# RTI0_CFG register map
Vendor: Texas Instruments
Peripheral module from a debugger description file (folder J7VCL).
Registers are 32-bit, read-write, reset 0x0 unless marked. A register's access mark holds for its fields unless they carry their own. Offsets are as the file gives them; lines under a group give offsets from that group; [hi:lo] are bit positions; {n}, {i} and the like mark numbered series; 'fields as' and 'values as' point back to an identical list; <NAME> marks a mode.

## RTI0_CFG
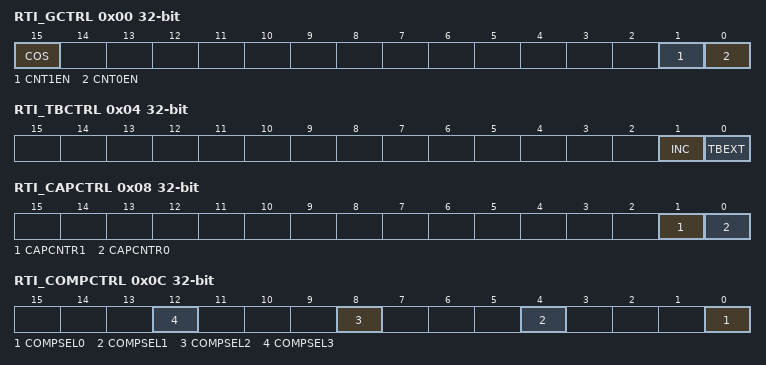
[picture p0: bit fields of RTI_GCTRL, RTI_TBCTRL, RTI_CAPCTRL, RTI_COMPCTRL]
0x00 RTI_GCTRL access per field
  [15] COS rw — Continue On Suspend. This bit determines if both counters are stopped when the device goes into debug mode or if they continue counting.
  [1] CNT1EN rw — Counter 1 Enable.
  [0] CNT0EN rw — Counter 0 Enable. The CNT0EN bit starts and stops the operation of counter block0 (UC0 and FRC0).
0x04 RTI_TBCTRL access per field
  [1] INC rw — This bit determines whether the Free Running Counter 0 is automatically incremented if a failing clock on the NTUx signal is detected.
  [0] TBEXT rw — The Timebase External bit selects whether the Free Running Counter 0 is clocked by the internal Up Counter 0 or from the external signal NTUx. Since setting the TBEXT bit to 1 resets Up Counter 0, Free Running Counter 0 will not be incremented in this occurence. The only source which is able to increment Free Running Counter 0 is NTUx. When the Timebase Supervisor circuit detects a missing clockedge, then the TBEXT bit is reset. The selection if the external signal should be used, can only be done by software.
0x08 RTI_CAPCTRL access per field
  [1] CAPCNTR1 rw — Capture Counter 1.
  [0] CAPCNTR0 rw — Capture Counter 0. This bit determines, which external interrupt source triggers a capture event of both UC0 and FRC0.
0x0C RTI_COMPCTRL access per field
  [4n] COMPSEL{n} rw (n=0..3) — Compare Select {n}. This bit determines the counter with which the compare value hold in compare register {n} is compared.
0x10 RTI_FRC0 — This registers holds the current value of the Free Running Counter 0 and will be updated continuously.
  [31:0] FRC0 — Free Running Counter 0. This registers holds the current value of the Free Running Counter 0 and will be updated continuously.
0x14 RTI_UC0
  [31:0] UC0 — Up Counter 0. This registers holds the current value of the Up Counter 0 and prescales the RTI clock. It will be only updated by a previous read of Free Running Counter 0. This gives effectively a 64 bit read of both counters, without having the problem of a counter being updated between two consecutive reads on Up Counter 0 and Free Running Counter 0.
0x18 RTI_CPUC0
  [31:0] CPUC0 — Compare Up Counter 0. This registers holds the compare value, which is compared with the Up Counter 0. When the compare matches, Free Running counter 0 is incremented. The Up Counter is set to zero when the counter value matches the CPUC0 value. The value set in this prescales the RTI.
0x20 RTI_CAFRC0 ro
  [31:0] CAFRC0 — Capture Free Running Counter 0. This registers captures the current value of the Free Running Counter 0 when an event occurs, controlled by the external capture control block.
0x24 RTI_CAUC0 ro
  [31:0] CAUC0 — Capture Up Counter 0. This registers captures the current value of the Up Counter 0 when an event occurs, controlled by the external capture control block. The read sequence has to be the same as with Up Counter 0 and Free Running Counter 0. So the
0x30 RTI_FRC1
  [31:0] FRC1 — Free Running Counter 1. This registers holds the current value of the Free Running Counter 1 and will be updated continuously.
0x34 RTI_UC1
  [31:0] UC1 — Up Counter 1. This registers holds the current value of the Up Counter 1 and prescales the RTI clock. It will be only updated by a previous read of Free Running Counter 1. This gives effectively a 64 bit read of both counters, without having the problem of a counter being updated between two consecutive reads on Up Counter 1 and Free Running Counter 1.
0x38 RTI_CPUC1
  [31:0] CPUC1 — Compare Up Counter 1. This registers holds the compare value, which is compared with the Up Counter 1. When the compare matches, Free Running counter 1 is incremented. The Up Counter is set to zero when the counter value matches the CPUC1 value. The value set in this prescales the RTI.
0x40 RTI_CAFRC1 ro
  [31:0] CAFRC1 — Capture Free Running Counter 1. This registers captures the current value of the Free Running Counter 1 when an event occurs, controlled by the external capture control block.
0x44 RTI_CAUC1 ro
  [31:0] CAUC1 — Capture Up Counter 1. This registers captures the current value of the Up Counter 1 when an event occurs, controlled by the external capture control block. The read sequence has to be the same as with Up Counter 1 and Free Running Counter 1. So the
{0x50+8i} RTI_COMP{i} (i=0..3)
  [31:0] COMP{i} — Compare {i}. This registers holds a compare value, which is compared with the counter selected in the compare control logic. If the Free Running Counter matches the compare value, an interrupt is flagged. With this register it is also possible to initiate a DMA request.
0x54 RTI_UDCP0
  [31:0] UDCP0 — Update Compare 0 Register. This registers holds a value, which is added to the value in the compare 0 register each time a compare matches. This gives the possibility to generate periodic interrupts without software intervention.
0x5C RTI_UDCP1
  [31:0] UDCP1 — Update Compare 1 Register. This registers holds a value, which is added to the value in the compare 1 register each time a compare matches. This gives the possibility to generate periodic interrupts without software intervention.
0x64 RTI_UDCP2 — This registers holds a value, which is added to the value in the compare 2 register each time a compare matches. This gives the possibility to generate periodic interrupts without software intervention.
  [31:0] UDCP2 — Update Compare 2 Register. This registers holds a value, which is added to the value in the compare 2 register each time a compare matches. This gives the possibility to generate periodic interrupts without software intervention.
0x6C RTI_UDCP3
  [31:0] UDCP3 — Update Compare 3 Register. This registers holds a value, which is added to the value in the compare 3 register each time a compare matches. This gives the possibility to generate periodic interrupts without software intervention.
0x70 RTI_TBLCOMP ro
  [31:0] TBLCOMP — Reserved
0x74 RTI_TBHCOMP ro
  [31:0] TBHCOMP — Reserved
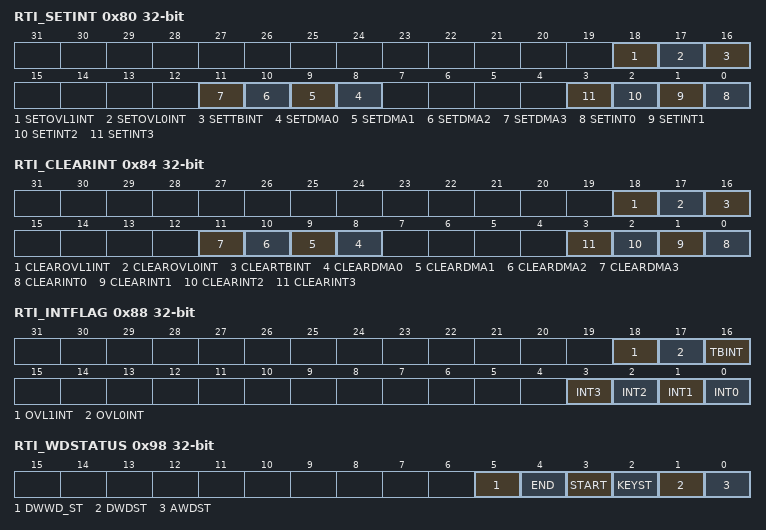
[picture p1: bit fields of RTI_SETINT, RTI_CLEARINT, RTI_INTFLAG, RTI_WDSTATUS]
0x80 RTI_SETINT access not given — This register prevents the necessity of a read-modify-write operation if a particular interrupt should be enabled. Some of the RTI features described in this section may not be supported on this family of devices. For more information, see , RTI Not Supported Features.
  [18] SETOVL1INT — Set Free Running Counter 1 Overflow Interrupt. (access RW1S)
  [17] SETOVL0INT — Set Free Running Counter 0 Overflow Interrupt. (access RW1S)
  [16] SETTBINT — User and privilege mode (read): (access RW1S)
  [n+8] SETDMA{n} (n=0..3) — Set Compare DMA Request {n}. (access RW1S)
  [n] SETINT{n} (n=0..3) — Set Compare Interrupt {n}. (access RW1S)
0x84 RTI_CLEARINT access not given — This register prevents the necessity of a read-modify-write operation if a particular interrupt should be disabled. Some of the RTI features described in this section may not be supported on this family of devices. For more information, see , RTI Not Supported Features.
  [18] CLEAROVL1INT — Clear Free Running Counter 1 Overflow Interrupt. (access RW1C)
  [17] CLEAROVL0INT — Clear Free Running Counter 0 Overflow Interrupt. (access RW1C)
  [16] CLEARTBINT — (access RW1C)
  [n+8] CLEARDMA{n} (n=0..3) — Clear Compare DMA Request {n}. (access RW1C)
  [n] CLEARINT{n} (n=0..3) — Clear Compare Interrupt {n}. (access RW1C)
0x88 RTI_INTFLAG access not given — The corresponding flags are set at every compare match of Free Running Counterx and RTICOMPx value, regardless if the interrupt is enabled or not.
  [18] OVL1INT — Free Running Counter 1 Overflow Interrupt Flag. (access RW1C)
  [17] OVL0INT — Free Running Counter 0 Overflow Interrupt Flag. (access RW1C)
  [16] TBINT — User and privilege mode (read): this flag is set when the TBEXT bit is cleared by detection of a missing external clockedge. It will not be set by clearing TBEXT by software. (access RW1C)
  [n] INT{n} (n=0..3) — Interrupt Flag {n}. (access RW1C)
0x90 RTI_DWDCTRL reset 0x5312ACED — Some of the RTI features described in this section may not be supported on this family of devices. For more information, see , RTI Not Supported Features. This register's functionality is dependent on whether the DWD is implemented to be always enabled or not. If the DWD is always enabled, then the DWD is automatically enabled after system reset is released and cannot be disabled by software. In that case, this register is redundant and any writes to this register have no effect on the DWD functionality. If, however, the DWD is not enabled upon release of system reset, then the software has to write to the DWDCTRL field in order to enable the DWD, as described below. Once enabled, the watchdog can only be disabled by a system reset. The application cannot disable the watchdog. The register also implements a one-time-write constraint. That is, once the application writes to this register to enable the watchdog, all further writes are ignored.
  [31:0] DWDCTRL — Digital Watchdog Control.
0x94 RTI_DWDPRLD access per field reset 0xFFF — Some of the RTI features described in this section may not be supported on this family of devices. For more information, see , RTI Not Supported Features.
  [11:0] DWDPRLD rw — Digital Watchdog Preload Value.
0x98 RTI_WDSTATUS access not given — Some of the RTI features described in this section may not be supported on this family of devices. For more information, see , RTI Not Supported Features. The values of the following status bits will not be affected by a system reset. These bits are cleared by a power up reset, or by the application.
  [5] DWWD_ST — Windowed Watchdog Status. This bit denotes whether the time-window defined by the windowed watchdog configuration has been violated, or if a wrong key or key sequence was written to service the watchdog. (access RW1C)
  [4] END — Windowed Watchdog End Time Violation Status. This bit denotes whether the end-time defined by the windowed watchdog configuration has been violated. This bit is effectively a copy of the DWD ST status flag. (access RW1C)
  [3] START — Windowed Watchdog End Time Violation Status. This bit denotes whether the start-time defined by the windowed watchdog configuration has been violated. This indicates that the WWD was serviced before the service window was opened. (access RW1C)
  [2] KEYST — Watchdog KeyStatus. This bit denotes a reset generated by a wrong key or a wrong key-sequence written to the (access RW1C)
  [1] DWDST — Digital Watchdog Status. Status flag and is maintained for compatibility reasons. (access RW1C)
  [0] AWDST — Analog Watchdog Status. (access RW1C)
0x9C RTI_WDKEY access per field reset 0xA35C — Some of the RTI features described in this section may not be supported on this family of devices. For more information, see , RTI Not Supported Features.
  [15:0] WDKEY rw — Watchdog Key.Example of a WDKEY sequenceStep -&gt; Value written to WDKEY -&gt; Result1 -&gt; 0x0A35C -&gt; No Action2 -&gt; 0x0A35C -&gt; No Action3 -&gt; 0x0E51A -&gt; WDKEY is enabled for reset by next 0x0A35C4 -&gt; 0x0E51A -&gt; WDKEY is enabled for reset by next 0x0A35C5 -&gt; 0x0E51A -&gt; WDKEY is enabled for reset by next 0x0A35C6 -&gt; 0x0A35C -&gt; Watchdog is reset7 -&gt; 0x0A35C -&gt; No Action8 -&gt; 0x0E51A -&gt; WDKEY is enabled for reset by next 0x0A35C9 -&gt; 0x0A35C -&gt; Watchdog is reset10 -&gt; 0x0E51A -&gt; WDKEY is enabled for reset by next 0x0A35C11 -&gt; 0x02345 -&gt; System reset; incorrect value written to WDKEY
0xA0 RTI_DWDCNTR ro reset 0x1FFFFFF — Some of the RTI features described in this section may not be supported on this family of devices. For more information, see , RTI Not Supported Features.
  [24:0] DWDCNTR — Digital Watchdog Down Counter. The value of the DWDCNTR after a system reset is 01FFFFFFh. When the DWD is enabled and the DWD counter starts counting down from this value with an RTI_FCLK time base of 3 MHz, a watchdog reset will be generated in 1 second.
0xA4 RTI_WWDRXNCTRL access per field reset 0x5
  [3:0] WWDRXN rw — Digital Windowed Watchdog Reaction.
0xA8 RTI_WWDSIZECTRL reset 0x5
  [31:0] WWDSIZE — Digital Windowed Watchdog Window Size.
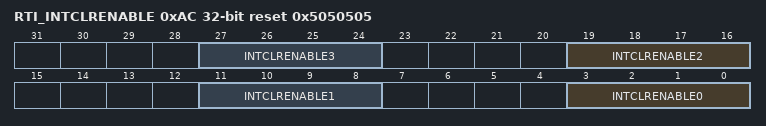
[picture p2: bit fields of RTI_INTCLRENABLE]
0xAC RTI_INTCLRENABLE access per field reset 0x5050505
  [8n+3:8n] INTCLRENABLE{n} rw (n=0..3) — Enables the auto-clear functionality on the compare {n} interrupt.
{0xB0+4i} RTI_COMP{i}CLR (i=0..3)
  [31:0] COMP{i}CLR — Compare {i} Clear. This registers holds a compare value, which is compared with the counter selected in the compare control logic. If the Free Running Counter matches the compare value, the compare {i} interrupt or DMA request line is cleared.
